AUTOSAR XML (schema 321)
package /ComponentType
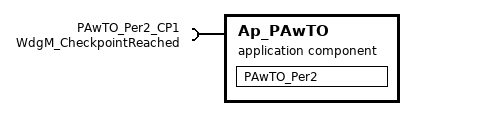
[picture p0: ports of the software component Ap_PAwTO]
  application software component type Ap_PAwTO
    require port PAwTO_Per2_CP1: client-com-spec=CheckpointReached, required-interface=WdgM_CheckpointReached
  internal behavior Ap_PAwTO_InternalBehavior: component=Ap_PAwTO, port-api-option{enable-take-address=false, indirect-api=false, port=PAwTO_Per2_CP1}
    runnable PAwTO_Per2
      sync call SC_PAwTO_Per2_CP1_CheckpointReached: operation=PAwTO_Per2_CP1.CheckpointReached, timeout=0
  swc implementation Ap_PAwTO_Implementation: behavior=Ap_PAwTO_InternalBehavior
    code-descriptors:
      code Code: type=SRC
package /PortInterface
  client server interface WdgM_CheckpointReached: is-service=true
    operation CheckpointReached: possible-error=E_NOT_OK  # Indicates to the Watchdog Manager that a Checkpoint within a Supervised Entity has been reached.
    error E_NOT_OK: error-code=1
